VERSION ""

NS_ :

BS_:

BU_: XXX

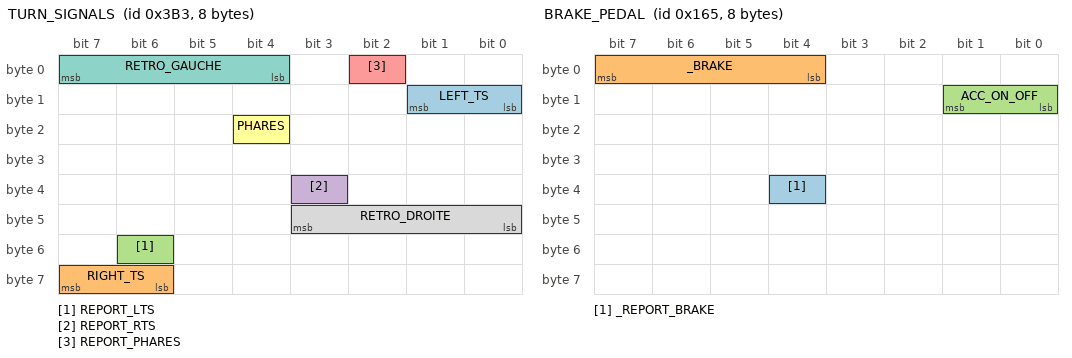
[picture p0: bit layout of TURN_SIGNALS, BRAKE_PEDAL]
BO_ 947 TURN_SIGNALS: 8 XXX
 SG_ LEFT_TS : 9|2@0+ (1,0) [0|1] "" XXX
 SG_ RIGHT_TS : 63|2@0+ (1,0) [0|1] "" XXX
 SG_ REPORT_LTS : 54|1@0+ (1,0) [0|1] "" XXX
 SG_ REPORT_RTS : 35|1@0+ (1,0) [0|1] "" XXX
 SG_ REPORT_PHARES : 2|1@0+ (1,0) [0|1] "" XXX
 SG_ PHARES : 20|1@0+ (1,0) [0|1] "" XXX
 SG_ RETRO_GAUCHE : 7|4@0+ (1,0) [0|1] "" XXX
 SG_ RETRO_DROITE : 43|4@0+ (1,0) [0|1] "" XXX

BO_ 357 BRAKE_PEDAL: 8 XXX
 SG_ _REPORT_BRAKE : 36|1@0+ (1,0) [0|1] "" XXX
 SG_ _BRAKE : 7|4@0+ (1,0) [0|15] "" XXX
 SG_ ACC_ON_OFF : 8|2@1+ (1,0) [0|3] "" XXX

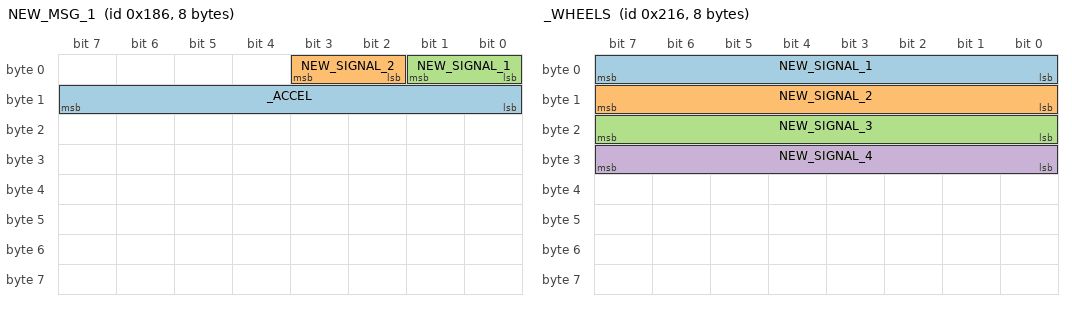
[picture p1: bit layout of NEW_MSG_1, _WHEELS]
BO_ 390 NEW_MSG_1: 8 XXX
 SG_ _ACCEL : 15|8@0- (1,0) [0|4095] "" XXX
 SG_ NEW_SIGNAL_2 : 2|2@1- (1,0) [0|3] "" XXX
 SG_ NEW_SIGNAL_1 : 0|2@1+ (1,0) [0|15] "" XXX

BO_ 377 NEW_MSG_2: 8 XXX

BO_ 534 _WHEELS: 8 XXX
 SG_ NEW_SIGNAL_1 : 7|8@0+ (1,0) [0|255] "" XXX
 SG_ NEW_SIGNAL_2 : 15|8@0+ (1,0) [0|255] "" XXX
 SG_ NEW_SIGNAL_3 : 23|8@0+ (1,0) [0|255] "" XXX
 SG_ NEW_SIGNAL_4 : 31|8@0+ (1,0) [0|255] "" XXX

BO_ 532 NEW_MSG_4: 8 XXX

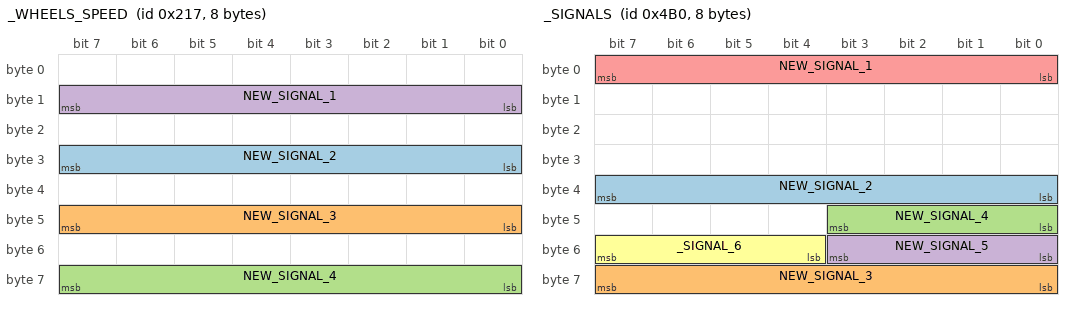
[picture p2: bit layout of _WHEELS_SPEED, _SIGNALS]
BO_ 535 _WHEELS_SPEED: 8 XXX
 SG_ NEW_SIGNAL_2 : 31|8@0+ (1,0) [0|255] "" XXX
 SG_ NEW_SIGNAL_3 : 47|8@0+ (1,0) [0|255] "" XXX
 SG_ NEW_SIGNAL_4 : 63|8@0+ (1,0) [0|255] "" XXX
 SG_ NEW_SIGNAL_1 : 15|8@0+ (1,0) [0|255] "" XXX

BO_ 560 NEW_MSG_3: 8 XXX
 SG_ _UNKNOWN : 7|2@0- (1,0) [0|65535] "" XXX

BO_ 514 SPEED: 8 XXX
 SG_ SPEED : 55|16@0+ (1,0) [0|65535] "" XXX
 SG_ _REAR_MODE : 0|4@1+ (1,0) [0|15] "" XXX

BO_ 1045 NEW_MSG_5: 8 XXX
 SG_ _SIGNAL_1 : 15|2@0+ (1,0) [0|255] "" XXX
 SG_ NEW_SIGNAL_2 : 63|8@0- (1,0) [0|255] "" XXX

BO_ 1200 _SIGNALS: 8 XXX
 SG_ NEW_SIGNAL_2 : 39|8@0+ (1,0) [0|255] "" XXX
 SG_ NEW_SIGNAL_3 : 63|8@0- (1,0) [0|255] "" XXX
 SG_ NEW_SIGNAL_4 : 43|4@0+ (1,0) [0|1] "" XXX
 SG_ NEW_SIGNAL_5 : 51|4@0+ (1,0) [0|1] "" XXX
 SG_ NEW_SIGNAL_1 : 7|8@0+ (1,0) [0|255] "" XXX
 SG_ _SIGNAL_6 : 55|4@0+ (1,0) [0|15] "" XXX

BO_ 145 _STEERING_ANGLE: 8 XXX
 SG_ NEW_SIGNAL_2 : 39|16@0+ (1,0) [0|16777215] "" XXX
 SG_ _DIRECTION : 23|16@0+ (1,0) [0|65535] "" XXX

BO_ 516 RPM: 8 XXX
 SG_ RPM : 31|16@0+ (1,0) [0|65535] "" XXX

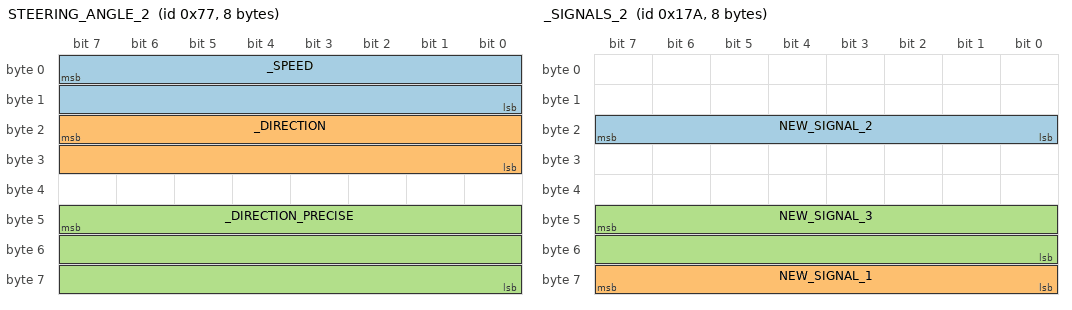
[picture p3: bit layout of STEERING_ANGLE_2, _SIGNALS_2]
BO_ 119 STEERING_ANGLE_2: 8 XXX
 SG_ _SPEED : 7|16@0+ (1,0) [0|255] "" XXX
 SG_ _DIRECTION : 23|16@0+ (1,0) [0|65535] "" XXX
 SG_ _DIRECTION_PRECISE : 47|24@0+ (1,0) [0|255] "" XXX

BO_ 120 NEW_MSG_7: 8 XXX

BO_ 125 _SENSORS: 8 XXX
 SG_ _RELATED_TO_BRAKES : 7|8@0+ (1,0) [0|255] "" XXX
 SG_ _ALERTE_COLLISION : 15|16@0+ (1,0) [0|65535] "" XXX

BO_ 378 _SIGNALS_2: 8 XXX
 SG_ NEW_SIGNAL_2 : 23|8@0+ (1,0) [0|255] "" XXX
 SG_ NEW_SIGNAL_1 : 63|8@0- (1,0) [0|65535] "" XXX
 SG_ NEW_SIGNAL_3 : 47|16@0+ (1,0) [0|65535] "" XXX

BO_ 391 _SIGNALS: 8 XXX
 SG_ _VOLTAGE2 : 47|8@0+ (1,0) [0|255] "" XXX
 SG_ _SIGNAL_1 : 15|8@0+ (1,0) [0|255] "" XXX

BO_ 133 _STEERING: 8 XXX
 SG_ _STEER : 7|16@0+ (1,0) [0|65535] "" XXX

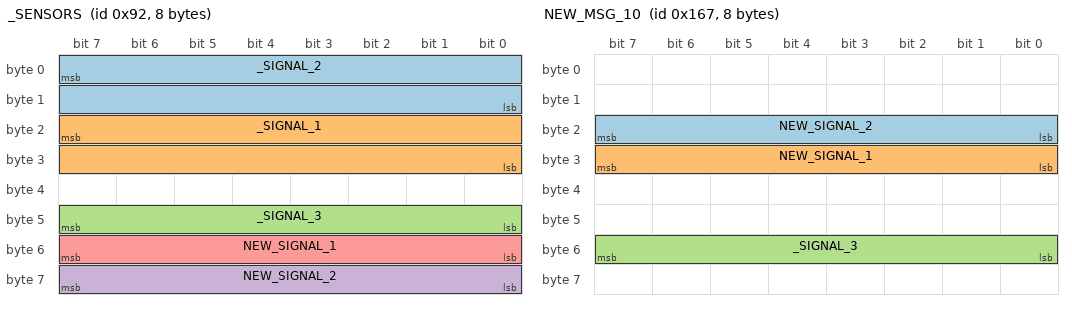
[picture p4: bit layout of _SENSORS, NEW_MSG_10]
BO_ 146 _SENSORS: 8 XXX
 SG_ _SIGNAL_2 : 7|16@0+ (1,0) [0|65535] "" XXX
 SG_ _SIGNAL_1 : 23|16@0+ (1,0) [0|65535] "" XXX
 SG_ _SIGNAL_3 : 47|8@0+ (1,0) [0|255] "" XXX
 SG_ NEW_SIGNAL_2 : 63|8@0+ (1,0) [0|255] "" XXX
 SG_ NEW_SIGNAL_1 : 55|8@0+ (1,0) [0|255] "" XXX

BO_ 330 _SPEED: 8 XXX
 SG_ NEW_SIGNAL_1 : 7|2@0+ (1,0) [0|255] "" XXX
 SG_ _SPEED : 23|16@0+ (1,0) [0|65535] "" XXX

BO_ 359 NEW_MSG_10: 8 XXX
 SG_ NEW_SIGNAL_2 : 23|8@0+ (1,0) [0|255] "" XXX
 SG_ NEW_SIGNAL_1 : 31|8@0+ (1,0) [0|255] "" XXX
 SG_ _SIGNAL_3 : 55|8@0- (1,0) [0|255] "" XXX

BO_ 118 NEW_MSG_11: 8 XXX
 SG_ _DIRECTION : 17|2@0+ (1,0) [0|255] "" XXX

CM_ SG_ 947 PHARES "ON OFF";
CM_ SG_ 947 RETRO_DROITE "BLIS ?";
CM_ SG_ 560 _UNKNOWN "avant ou arriere";
CM_ SG_ 1045 _SIGNAL_1 "deplacement du vehicule";
CM_ SG_ 146 _SIGNAL_1 "G-FORCE ?";
CM_ SG_ 330 _SPEED "or acceleration ?";
CM_ SG_ 359 NEW_SIGNAL_1 "related to motor";
CM_ SG_ 118 _DIRECTION "GO AHEAD (3) OR GO REAR (1) ?";
